VERSION "0.1"

NS_ :

BS_:

BU_: BMS VCU Tester

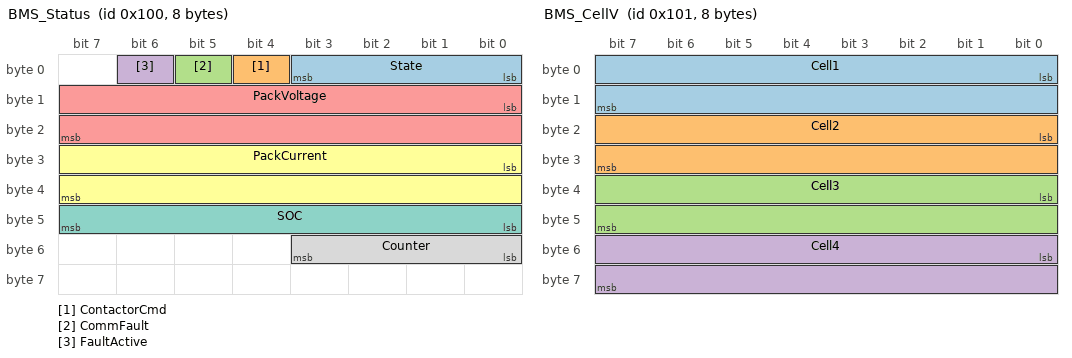
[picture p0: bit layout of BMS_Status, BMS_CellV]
BO_ 256 BMS_Status: 8 BMS
 SG_ State : 0|4@1+ (1,0) [0|3] "" VCU
 SG_ ContactorCmd : 4|1@1+ (1,0) [0|1] "" VCU
 SG_ CommFault : 5|1@1+ (1,0) [0|1] "" VCU
 SG_ FaultActive : 6|1@1+ (1,0) [0|1] "" VCU
 SG_ PackVoltage : 8|16@1+ (0.001,0) [0|65.535] "V" VCU
 SG_ PackCurrent : 24|16@1- (0.1,0) [-3276.8|3276.7] "A" VCU
 SG_ SOC : 40|8@1+ (0.5,0) [0|100] "%" VCU
 SG_ Counter : 48|4@1+ (1,0) [0|15] "" VCU

BO_ 257 BMS_CellV: 8 BMS
 SG_ Cell1 : 0|16@1+ (0.001,0) [0|65.535] "V" VCU
 SG_ Cell2 : 16|16@1+ (0.001,0) [0|65.535] "V" VCU
 SG_ Cell3 : 32|16@1+ (0.001,0) [0|65.535] "V" VCU
 SG_ Cell4 : 48|16@1+ (0.001,0) [0|65.535] "V" VCU

BO_ 258 BMS_Temp: 4 BMS
 SG_ Temp1 : 0|16@1- (0.1,0) [-3276.8|3276.7] "degC" VCU
 SG_ Temp2 : 16|16@1- (0.1,0) [-3276.8|3276.7] "degC" VCU

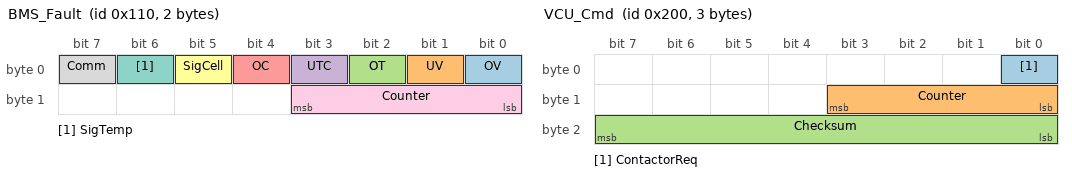
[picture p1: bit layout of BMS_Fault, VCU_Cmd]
BO_ 272 BMS_Fault: 2 BMS
 SG_ OV : 0|1@1+ (1,0) [0|1] "" VCU
 SG_ UV : 1|1@1+ (1,0) [0|1] "" VCU
 SG_ OT : 2|1@1+ (1,0) [0|1] "" VCU
 SG_ UTC : 3|1@1+ (1,0) [0|1] "" VCU
 SG_ OC : 4|1@1+ (1,0) [0|1] "" VCU
 SG_ SigCell : 5|1@1+ (1,0) [0|1] "" VCU
 SG_ SigTemp : 6|1@1+ (1,0) [0|1] "" VCU
 SG_ Comm : 7|1@1+ (1,0) [0|1] "" VCU
 SG_ Counter : 8|4@1+ (1,0) [0|15] "" VCU

BO_ 512 VCU_Cmd: 3 VCU
 SG_ ContactorReq : 0|1@1+ (1,0) [0|1] "" BMS
 SG_ Counter : 8|4@1+ (1,0) [0|15] "" BMS
 SG_ Checksum : 16|8@1+ (1,0) [0|255] "" BMS

BO_ 2016 UDS_Request: 8 Tester
 SG_ Payload : 0|64@1+ (1,0) [0|0] "" BMS

BO_ 2024 UDS_Response: 8 BMS
 SG_ Payload : 0|64@1+ (1,0) [0|0] "" Tester

CM_ "BMS CAN database v0.1 for the portfolio project. 500 kbit/s classic CAN. Values are design assumptions.";
CM_ BO_ 256 "Pack status. SWR-017: 100 ms +/- 10 ms.";
CM_ BO_ 257 "Cell voltages. SWR-018: 100 ms +/- 10 ms.";
CM_ BO_ 258 "Temperatures. SWR-018: 100 ms +/- 10 ms.";
CM_ BO_ 272 "Fault flags. SWR-019: sent within 10 ms of a fault, then every 100 ms while the fault persists.";
CM_ BO_ 512 "Contactor request from VCU. SWR-015: timeout 300 ms. SWR-016: counter and checksum.";
CM_ SG_ 512 Checksum "CRC-8 SAE J1850 (poly 0x1D, init 0xFF, xorout 0xFF) over bytes 0-1. Borrowed from the E2E protection idea; not an implementation of an AUTOSAR E2E profile.";
CM_ BO_ 2016 "UDS physical request (ISO-TP). Payload is raw ISO-TP frames.";
CM_ BO_ 2024 "UDS response (ISO-TP). Payload is raw ISO-TP frames.";

BA_DEF_ BO_ "GenMsgCycleTime" INT 0 10000;
BA_DEF_ BO_ "GenMsgSendType" STRING ;
BA_DEF_DEF_ "GenMsgCycleTime" 0;
BA_DEF_DEF_ "GenMsgSendType" "Cyclic";

BA_ "GenMsgCycleTime" BO_ 256 100;
BA_ "GenMsgCycleTime" BO_ 257 100;
BA_ "GenMsgCycleTime" BO_ 258 100;
BA_ "GenMsgCycleTime" BO_ 272 100;
BA_ "GenMsgSendType" BO_ 272 "CyclicIfActive";
BA_ "GenMsgCycleTime" BO_ 512 100;
BA_ "GenMsgSendType" BO_ 2016 "Event";
BA_ "GenMsgSendType" BO_ 2024 "Event";

VAL_ 256 State 0 "INIT" 1 "STANDBY" 2 "CLOSED" 3 "FAULT" ;
VAL_ 256 SOC 255 "Not Available" ;
